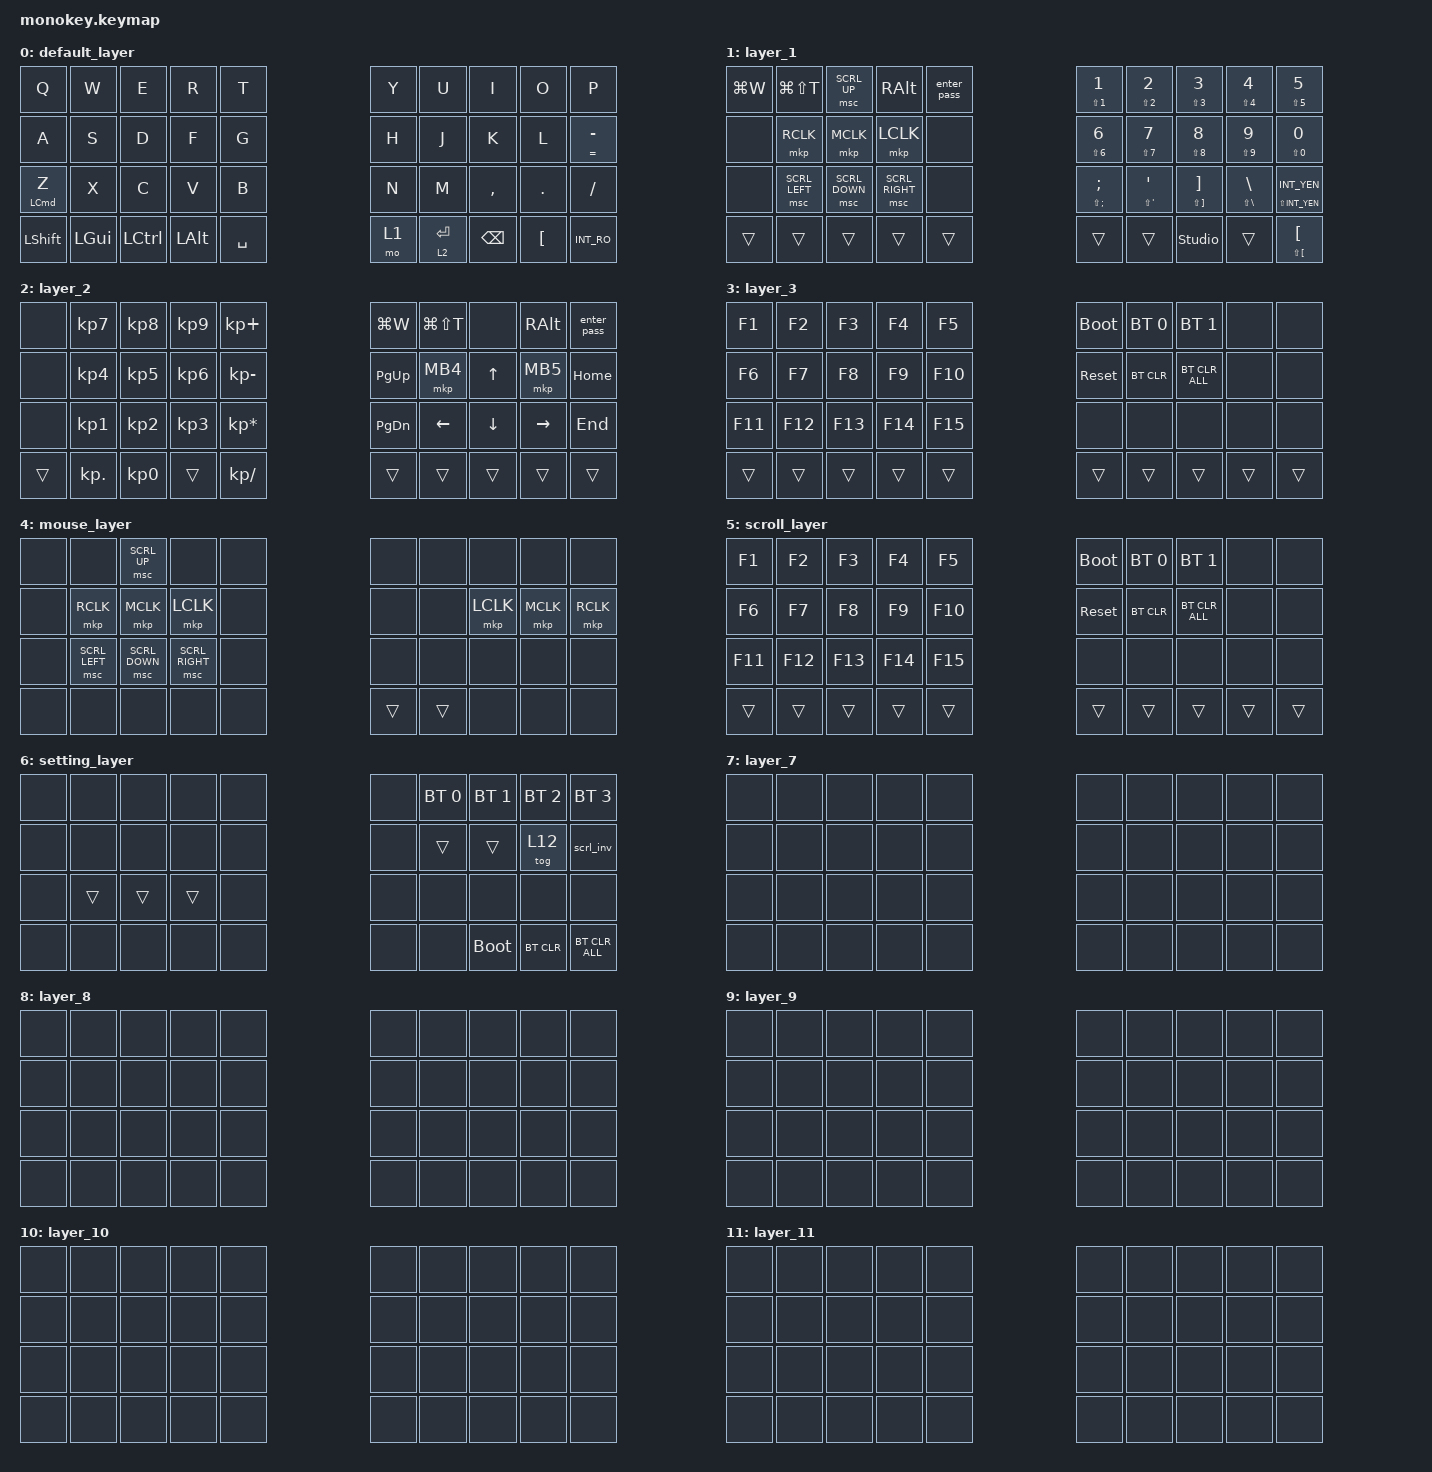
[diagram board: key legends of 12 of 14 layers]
/*
 * Copyright (c) 2024 Conductor Keyboard
 * Generated by Conductor Studio 2.0
 */

#include <dt-bindings/zmk/mouse.h>
#include <behaviors.dtsi>
#include <dt-bindings/zmk/bt.h>
#include <dt-bindings/zmk/keys.h>
#include <dt-bindings/zmk/pointing.h>

&mt {
    flavor = "tap-preferred";
    quick-tap-ms = <0>;
};

&lt {
    quick-tap-ms = <300>;
    flavor = "tap-preferred";
};

/ {
    combos {
        compatible = "zmk,combos";

        esc {
            bindings = <&kp ESC>;
            key-positions = <0 1>;
            timeout-ms = <50>;
        };

        tab {
            bindings = <&kp TAB>;
            key-positions = <10 11>;
            timeout-ms = <50>;
        };

        scroll {
            bindings = <&mo 5>;
            key-positions = <18 19>;
            timeout-ms = <50>;
        };

        eisu {
            bindings = <&kp LANG2>;
            key-positions = <23 24>;
            timeout-ms = <50>;
        };

        kana {
            bindings = <&kp LANG1>;
            key-positions = <25 26>;
            timeout-ms = <50>;
        };

        gesture {
            bindings = <&mo 13>;
            key-positions = <29 28>;
            timeout-ms = <50>;
        };
    };

    macros {
        enter_pass: enter_pass {
            compatible = "zmk,behavior-macro";
            #binding-cells = <0>;
            bindings = <&none>; // ENTER_PASS_PH
            label = "ENTER_PASS";
        };
    };

    keymap {
        compatible = "zmk,keymap";

        default_layer {
            bindings = <
&kp Q               &kp W     &kp E      &kp R     &kp T                          &kp Y     &kp U  &kp I      &kp O     &kp P
&kp A               &kp S     &kp D      &kp F     &kp G                          &kp H     &kp J  &kp K      &kp L     &mt EQUAL MINUS
&mt LEFT_COMMAND Z  &kp X     &kp C      &kp V     &kp B                          &kp N     &kp M  &kp COMMA  &kp DOT   &kp SLASH
&kp LSHIFT          &kp LGUI  &kp LCTRL  &kp LALT  &kp SPACE  &mo 1  &lt 2 ENTER  &kp BSPC                    &kp LBKT  &kp INT_RO
            >;

            sensor-bindings = <&inc_dec_kp PG_UP PG_DN>;
        };

        layer_1 {
            bindings = <
&kp LG(W)  &kp LG(LS(T))   &msc SCRL_UP    &kp RALT         &enter_pass                  &mt LS(N1) N1      &mt LS(N2) N2    &mt LS(N3) N3      &mt LS(N4) N4      &mt LS(N5) N5
&none      &mkp RCLK       &mkp MCLK       &mkp LCLK        &none                        &mt LS(N6) N6      &mt LS(N7) N7    &mt LS(N8) N8      &mt LS(N9) N9      &mt LS(N0) N0
&none      &msc SCRL_LEFT  &msc SCRL_DOWN  &msc SCRL_RIGHT  &none                        &mt LS(SEMI) SEMI  &mt LS(SQT) SQT  &mt LS(RBKT) RBKT  &mt LS(BSLH) BSLH  &mt LS(INT_YEN) INT_YEN
&trans     &trans          &trans          &trans           &trans       &trans  &trans  &studio_unlock                                         &trans             &mt LS(LBKT) LBKT
            >;
        };

        layer_2 {
            bindings = <
&none   &kp KP_N7   &kp KP_N8  &kp KP_N9  &kp KP_PLUS                      &kp LG(W)  &kp LG(LS(T))  &none     &kp RALT   &enter_pass
&none   &kp KP_N4   &kp KP_N5  &kp KP_N6  &kp KP_MINUS                     &kp PG_UP  &mkp MB4       &kp UP    &mkp MB5   &kp HOME
&none   &kp KP_N1   &kp KP_N2  &kp KP_N3  &kp KP_MULTIPLY                  &kp PG_DN  &kp LEFT       &kp DOWN  &kp RIGHT  &kp END
&trans  &kp KP_DOT  &kp KP_N0  &trans     &kp KP_SLASH     &trans  &trans  &trans                              &trans     &trans
            >;
        };

        layer_3 {
            bindings = <
&kp F1   &kp F2   &kp F3   &kp F4   &kp F5                   &bootloader  &bt BT_SEL 0  &bt BT_SEL 1    &none   &none
&kp F6   &kp F7   &kp F8   &kp F9   &kp F10                  &sys_reset   &bt BT_CLR    &bt BT_CLR_ALL  &none   &none
&kp F11  &kp F12  &kp F13  &kp F14  &kp F15                  &none        &none         &none           &none   &none
&trans   &trans   &trans   &trans   &trans   &trans  &trans  &trans                                     &trans  &trans
            >;
        };

        mouse_layer {
            bindings = <
&none  &none           &msc SCRL_UP    &none            &none                  &none  &none  &none      &none      &none
&none  &mkp RCLK       &mkp MCLK       &mkp LCLK        &none                  &none  &none  &mkp LCLK  &mkp MCLK  &mkp RCLK
&none  &msc SCRL_LEFT  &msc SCRL_DOWN  &msc SCRL_RIGHT  &none                  &none  &none  &none      &none      &none
&none  &none           &none           &none            &none  &trans  &trans  &none                    &none      &none
            >;
        };

        scroll_layer {
            bindings = <
&kp F1   &kp F2   &kp F3   &kp F4   &kp F5                   &bootloader  &bt BT_SEL 0  &bt BT_SEL 1    &none   &none
&kp F6   &kp F7   &kp F8   &kp F9   &kp F10                  &sys_reset   &bt BT_CLR    &bt BT_CLR_ALL  &none   &none
&kp F11  &kp F12  &kp F13  &kp F14  &kp F15                  &none        &none         &none           &none   &none
&trans   &trans   &trans   &trans   &trans   &trans  &trans  &trans                                     &trans  &trans
            >;
        };

        setting_layer {
            bindings = <
&none  &none   &none   &none   &none                &none        &bt BT_SEL 0  &bt BT_SEL 1  &bt BT_SEL 2  &bt BT_SEL 3
&none  &none   &none   &none   &none                &none        &trans        &trans        &tog 12       &scrl_inv
&none  &trans  &trans  &trans  &none                &none        &none         &none         &none         &none
&none  &none   &none   &none   &none  &none  &none  &bootloader                              &bt BT_CLR    &bt BT_CLR_ALL
            >;
        };

        layer_7 {
            bindings = <
&none  &none  &none  &none  &none                &none  &none  &none  &none  &none
&none  &none  &none  &none  &none                &none  &none  &none  &none  &none
&none  &none  &none  &none  &none                &none  &none  &none  &none  &none
&none  &none  &none  &none  &none  &none  &none  &none                &none  &none
            >;
        };

        layer_8 {
            bindings = <
&none  &none  &none  &none  &none                &none  &none  &none  &none  &none
&none  &none  &none  &none  &none                &none  &none  &none  &none  &none
&none  &none  &none  &none  &none                &none  &none  &none  &none  &none
&none  &none  &none  &none  &none  &none  &none  &none                &none  &none
            >;
        };

        layer_9 {
            bindings = <
&none  &none  &none  &none  &none                &none  &none  &none  &none  &none
&none  &none  &none  &none  &none                &none  &none  &none  &none  &none
&none  &none  &none  &none  &none                &none  &none  &none  &none  &none
&none  &none  &none  &none  &none  &none  &none  &none                &none  &none
            >;
        };

        layer_10 {
            bindings = <
&none  &none  &none  &none  &none                &none  &none  &none  &none  &none
&none  &none  &none  &none  &none                &none  &none  &none  &none  &none
&none  &none  &none  &none  &none                &none  &none  &none  &none  &none
&none  &none  &none  &none  &none  &none  &none  &none                &none  &none
            >;
        };

        layer_11 {
            bindings = <
&none  &none  &none  &none  &none                &none  &none  &none  &none  &none
&none  &none  &none  &none  &none                &none  &none  &none  &none  &none
&none  &none  &none  &none  &none                &none  &none  &none  &none  &none
&none  &none  &none  &none  &none  &none  &none  &none                &none  &none
            >;
        };

        /* PRECISION layer (id=12): when active, trackball movement is scaled
         * down for fine cursor control. Toggle with &tog 12. */

        precision_layer {
            bindings = <
&none  &none  &none  &none  &none                &none  &none  &none     &none     &none
&none  &none  &none  &none  &none                &none  &none  &mkp MB1  &mkp MB2  &mkp MB3
&none  &none  &none  &none  &none                &none  &none  &none     &none     &none
&none  &none  &none  &none  &none  &none  &none  &none                   &none     &tog 12
            >;
        };

        /* GESTURE layer (id=13): trackball swipe directions → Mission Control gestures.
         * I/J/L/comma positions map to up/left/right/down (Ctrl+arrow). */

        gesture_layer {
            bindings = <
&none  &none  &none  &none  &none                &none  &none         &kp LC(UP)    &none          &none
&none  &none  &none  &none  &none                &none  &kp LC(LEFT)  &none         &kp LC(RIGHT)  &none
&none  &none  &none  &none  &none                &none  &none         &kp LC(DOWN)  &none          &none
&none  &none  &none  &none  &none  &none  &none  &none                              &none          &none
            >;
        };
    };
};
